# GSC_0.1 register map
Vendor: Texas Instruments
Peripheral module from a debugger description file (folder mspm33c321x).
Registers are 32-bit, read-write, no defined reset value unless marked. A register's access mark holds for its fields unless they carry their own. Offsets are as the file gives them; lines under a group give offsets from that group; [hi:lo] are bit positions; {n}, {i} and the like mark numbered series; 'fields as' and 'values as' point back to an identical list; <NAME> marks a mode.

## GSC
0x1000 GSC_SPC_ATTRIBVIOLS_CONFIG — SRAM Secure Access Attribute Violation Configuration Register
  [0] SECVIOL — Controls the behavior of secure access to non-secure SRAM #br#0: Access is allowed #br#1: Access generates bus-fault and NMI
0x1004 GSC_SPC_ATTRIBVIOLP_CONFIG — SRAM Privilege Access Attribute Violation Configuration Register
  [0] PRIVVIOL — Controls the behavior of privilege access to non-privilege SRAM #br#0: Access is allowed #br#1: Access generates bus-fault and NMI
0x1010 GSC_PPC_ATTRIBVIOLS_CONFIG — Peripheral Secure Access Attribute Violation Configuration Register
  [0] SECVIOL — Controls the behavior of secure access to non-secure peripheral #br#0: Access is allowed #br#1: Access generates bus-fault and NMI
0x1014 GSC_PPC_ATTRIBVIOLP_CONFIG — Peripheral Privilege Access Attribute Violation Configuration Register
  [0] PRIVVIOL — Controls the behavior of privilege access to non-privilege peripherals #br#0: Access is allowed #br#1: Access generates bus-fault and NMI
0x1020 GSC_FPC_ATTRIBVIOLS_CONFIG — Flash Secure Access Attribute Violation Configuration Register
  [0] SECVIOL — Controls the behavior of secure access to non-secure Flash #br#0: Access is allowed #br#1: Access generates bus-fault and NMI
0x1024 GSC_FPC_ATTRIBVIOLP_CONFIG — Flash Privilege Access Attribute Violation Configuration Register
  [0] PRIVVIOL — Controls the behavior of privilege access to non-privilege Flash #br#0: Access is allowed #br#1: Access generates bus-fault and NMI
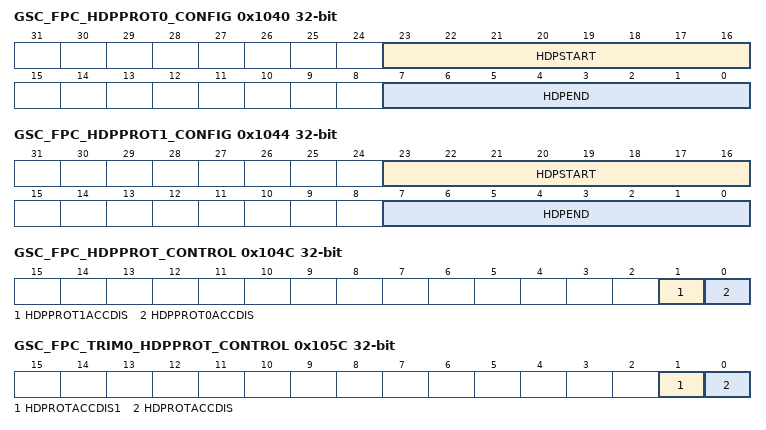
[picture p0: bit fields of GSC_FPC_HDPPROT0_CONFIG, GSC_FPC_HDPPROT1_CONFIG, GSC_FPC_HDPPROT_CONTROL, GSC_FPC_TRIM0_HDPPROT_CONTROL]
0x1040 GSC_FPC_HDPPROT0_CONFIG — Flash Hide Protection for Bank0 Configuration Register
  [23:16] HDPSTART — Sector number where hide protection starts
  [7:0] HDPEND — Sector number where hide protection ends
0x1044 GSC_FPC_HDPPROT1_CONFIG — Flash Hide Protection for Bank1 Configuration Register
  fields as GSC_FPC_HDPPROT0_CONFIG
0x104C GSC_FPC_HDPPROT_CONTROL — Flash Hide Protection Control Register
  [1] HDPPROT1ACCDIS — Enables the FPC_HDPPROT1_CONFIG to take effect. #br#0: HDP region access is enabled #br#1: HDP region access is disabled
  [0] HDPPROT0ACCDIS — Enables the FPC_HDPPROT0_CONFIG to take effect. #br#0: HDP region access is enabled #br#1: HDP region access is disabled
0x1050 GSC_FPC_HDPEN_CONTROL — Flash Hide Protection Enable Control Register
  [0] HDPEN — HDP mode enable. This bit is set in the OTP during provisioning. #br#0: HDP mode is not used #br#1: HDP mode is enabled
0x1054 GSC_FPC_NONMAIN0_HDPPROT_CONTROL — Flash NONMAIN Bank0 Hide Protection Control Register
  [3:0] HDPROTACCDIS — Enable HDP access to NONMAIN region #br#0: HDP region access is enabled #br#1: HDP region access is disabled
0x1058 GSC_FPC_NONMAIN1_HDPPROT_CONTROL — Flash NONMAIN Bank1 Hide Protection Control Register
  fields as GSC_FPC_NONMAIN0_HDPPROT_CONTROL
0x105C GSC_FPC_TRIM0_HDPPROT_CONTROL — Flash TRIM Bank0 Hide Protection Control Register
  [1] HDPROTACCDIS1 — No functionality implemented for this bit
  [0] HDPROTACCDIS — Enable HDP access to TRIM region #br#0: HDP region access is enabled #br#1: HDP region access is disabled
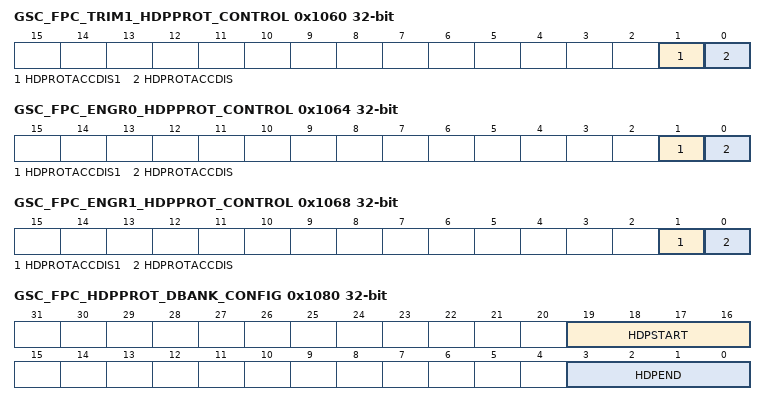
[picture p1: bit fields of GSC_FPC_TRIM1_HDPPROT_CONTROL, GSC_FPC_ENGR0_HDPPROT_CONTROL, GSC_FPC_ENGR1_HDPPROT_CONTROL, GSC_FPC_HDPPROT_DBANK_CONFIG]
0x1060 GSC_FPC_TRIM1_HDPPROT_CONTROL — Flash TRIM Bank1 Hide Protection Control Register
  fields as GSC_FPC_TRIM0_HDPPROT_CONTROL
0x1064 GSC_FPC_ENGR0_HDPPROT_CONTROL — Flash ENGR Bank0 Hide Protection Control Register
  [1] HDPROTACCDIS1 — No functionality implemented for this bit
  [0] HDPROTACCDIS — Enable HDP access to ENGR region #br#0: HDP region access is enabled #br#1: HDP region access is disabled
0x1068 GSC_FPC_ENGR1_HDPPROT_CONTROL — Flash ENGR Bank1 Hide Protection Control Register
  fields as GSC_FPC_ENGR0_HDPPROT_CONTROL
0x1080 GSC_FPC_HDPPROT_DBANK_CONFIG — Data Flash Hide Protection Configuration Register
  [19:16] HDPSTART — Sector number where hide protection starts
  [3:0] HDPEND — Sector number where hide protection ends
0x1084 GSC_FPC_HDPPROT_DBANK_CONTROL — Data Flash Hide Protection Control Register
  [0] HDPPROTACCDIS — Enables the HDP register to take effect for Databank #br#0: HDP region access is enabled #br#1: HDP region access is disabled
0x1088 GSC_FPC_HDPEN_DBANK_CONTROL — Data Flash Hide Protection Enable Control Register
  [0] HDPEN — HDP mode enable. This bit is set in the OTP during provisioning and copied from the OTP memory during boot by BOOTROM. #br#0: HDP mode is not used #br#1: HDP mode is enabled
0x108C GSC_FPC_NONMAIN_HDPPROT_DBANK_CONTROL — Data Flash NONMAIN Hide Protection Control Register
  fields as GSC_FPC_NONMAIN0_HDPPROT_CONTROL
0x1090 GSC_FPC_TRIM_HDPPROT_DBANK_CONTROL — Data Flash TRIM Hide Protection Control Register
  [1:0] HDPROTACCDIS — Enable HDP access to TRIM region #br#0: HDP region access is enabled #br#1: HDP region access is disabled
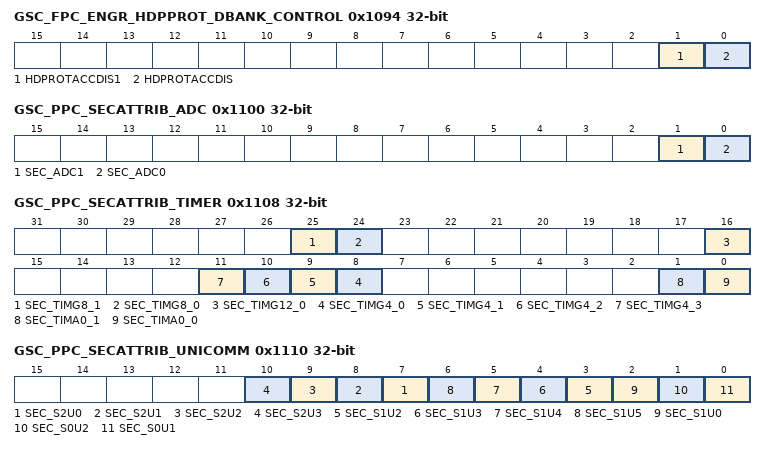
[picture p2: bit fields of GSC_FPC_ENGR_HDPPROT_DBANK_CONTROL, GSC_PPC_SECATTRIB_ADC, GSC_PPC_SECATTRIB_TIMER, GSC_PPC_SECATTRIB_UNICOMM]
0x1094 GSC_FPC_ENGR_HDPPROT_DBANK_CONTROL — Data Flash ENGR Hide Protection Control Register
  fields as GSC_FPC_ENGR0_HDPPROT_CONTROL
0x1100 GSC_PPC_SECATTRIB_ADC — Peripheral Secure Access ADC
  [1] SEC_ADC1 — Secure access enabled to ADC1 #br#0: Non-secure access is enabled #br#1: Secure access is enabled
  [0] SEC_ADC0 — Secure access enabled to ADC0 #br#0: Non-secure access is enabled #br#1: Secure access is enabled
0x1108 GSC_PPC_SECATTRIB_TIMER — Peripheral Secure Access Timer
  [25] SEC_TIMG8_1 — Secure access enabled to TIMG8_1 #br#0: Non-secure access is enabled #br#1: Secure access is enabled
  [24] SEC_TIMG8_0 — Secure access enabled to TIMG8_0 #br#0: Non-secure access is enabled #br#1: Secure access is enabled
  [16] SEC_TIMG12_0 — Secure access enabled to TIMG12_0 #br#0: Non-secure access is enabled #br#1: Secure access is enabled
  [n+8] SEC_TIMG4_{n} (n=0..3) — Secure access enabled to TIMG4_{n} #br#0: Non-secure access is enabled #br#1: Secure access is enabled
  [1] SEC_TIMA0_1 — Secure access enabled to TIMA0_1 #br#0: Non-secure access is enabled #br#1: Secure access is enabled
  [0] SEC_TIMA0_0 — Secure access enabled to TIMA0_0 #br#0: Non-secure access is enabled #br#1: Secure access is enabled
0x1110 GSC_PPC_SECATTRIB_UNICOMM — Peripheral Secure Access UniComm
  [n+7] SEC_S2U{n} (n=0..3) — Secure access enabled to UniComm S2U{n} #br#0: Non-secure access is enabled #br#1: Secure access is enabled
  [n+1] SEC_S1U{n} (n=2..5) — Secure access enabled to UniComm S1U{n} #br#0: Non-secure access is enabled #br#1: Secure access is enabled
  [2] SEC_S1U0 — Secure access enabled to UniComm S1U0 #br#0: Non-secure access is enabled #br#1: Secure access is enabled
  [1] SEC_S0U2 — Secure access enabled to UniComm S0U2 #br#0: Non-secure access is enabled #br#1: Secure access is enabled
  [0] SEC_S0U1 — Secure access enabled to UniComm S0U1 #br#0: Non-secure access is enabled #br#1: Secure access is enabled
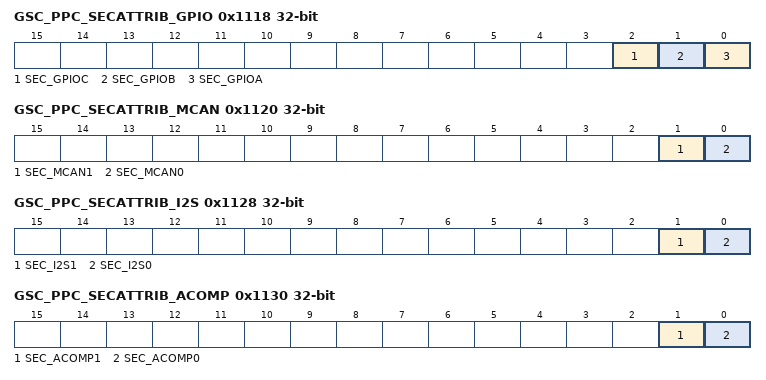
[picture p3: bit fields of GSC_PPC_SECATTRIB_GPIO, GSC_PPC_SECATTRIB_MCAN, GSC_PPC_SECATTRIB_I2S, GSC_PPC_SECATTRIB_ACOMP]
0x1118 GSC_PPC_SECATTRIB_GPIO — Peripheral Secure Access GPIO
  [2] SEC_GPIOC — Secure access enabled to GPIO C #br#0: Non-secure access is enabled #br#1: Secure access is enabled
  [1] SEC_GPIOB — Secure access enabled to GPIO B #br#0: Non-secure access is enabled #br#1: Secure access is enabled
  [0] SEC_GPIOA — Secure access enabled to GPIO A #br#0: Non-secure access is enabled #br#1: Secure access is enabled
0x1120 GSC_PPC_SECATTRIB_MCAN — Peripheral Secure Access CAN
  [1] SEC_MCAN1 — Secure access enabled to MCAN 1 #br#0: Non-secure access is enabled #br#1: Secure access is enabled
  [0] SEC_MCAN0 — Secure access enabled to MCAN 0 #br#0: Non-secure access is enabled #br#1: Secure access is enabled
0x1128 GSC_PPC_SECATTRIB_I2S — Peripheral Secure Access I2S
  [1] SEC_I2S1 — Secure access enabled to I2S 1 #br#0: Non-secure access is enabled #br#1: Secure access is enabled
  [0] SEC_I2S0 — Secure access enabled to I2S 0 #br#0: Non-secure access is enabled #br#1: Secure access is enabled
0x1130 GSC_PPC_SECATTRIB_ACOMP — Peripheral Secure Access Analog Comp
  [1] SEC_ACOMP1 — Secure access enabled to Comparator 1 #br#0: Non-secure access is enabled #br#1: Secure access is enabled
  [0] SEC_ACOMP0 — Secure access enabled to Comparator 0 #br#0: Non-secure access is enabled #br#1: Secure access is enabled
0x1138 GSC_PPC_SECATTRIB_WDT — Peripheral Secure Access Watchdog
  [0] SEC_WWDT — Secure access enabled to Windowed Watchdog #br#0: Non-secure access is enabled #br#1: Secure access is enabled
0x1140 GSC_PPC_SECATTRIB_LFSS — Peripheral Secure Access LFSS
  [0] SEC_LFSS — Secure access enabled to LFSS (including peripherals inside LFSS e.g. IWDT) #br#0: Non-secure access is enabled #br#1: Secure access is enabled
0x1148 GSC_PPC_SECATTRIB_CRC — Peripheral Secure Access CRC
  [0] SEC_CRC — Secure access enabled to CRC #br#0: Non-secure access is enabled #br#1: Secure access is enabled
0x1150 GSC_PPC_SECATTRIB_AES — Peripheral Secure Access AES
  [0] SEC_AES — Secure access enabled to AES #br#0: Non-secure access is enabled #br#1: Secure access is enabled
0x1158 GSC_PPC_SECATTRIB_SHA — Peripheral Secure Access SHA
  [0] SEC_SHA — Secure access enabled to SHA #br#0: Non-secure access is enabled #br#1: Secure access is enabled
0x1160 GSC_PPC_SECATTRIB_PKA — Peripheral Secure Access PKA
  [0] SEC_PKA — Secure access enabled to PKA #br#0: Non-secure access is enabled #br#1: Secure access is enabled
0x1168 GSC_PPC_SECATTRIB_IOMUX — Peripheral Secure Access IOMUX
  [0] SEC_IOMUX — Secure access enabled to IOMUX #br#0: Non-secure access is enabled #br#1: Secure access is enabled
0x1170 GSC_PPC_SECATTRIB_QSPI — Peripheral Secure Access QSPI
  [0] SEC_QSPI — Secure access enabled to QSPI #br#0: Non-secure access is enabled #br#1: Secure access is enabled
0x1178 GSC_PPC_SECATTRIB_TRNG — Peripheral Secure Access TRNG
  [0] SEC_TRNG — Secure access enabled to TRNG #br#0: Non-secure access is enabled #br#1: Secure access is enabled
0x1180 GSC_PPC_SECATTRIB_DEBUGSS — Peripheral Secure Access DEBUGSS
  [0] SEC_DEBUGSS — Secure access enabled to DEBUGSS #br#0: Non-secure access is enabled #br#1: Secure access is enabled
0x1188 GSC_PPC_SECATTRIB_VREF — Peripheral Secure Access VREF
  [0] SEC_VREF — Secure access enabled to VREF #br#0: Non-secure access is enabled #br#1: Secure access is enabled
0x1190 GSC_PPC_SECATTRIB_KEYSTORECTL — Peripheral Secure Access KEYSTORECTL
  [0] SEC_KEYSTORECTL — Secure access enabled to KEYSTORECTL #br#0: Non-secure access is enabled #br#1: Secure access is enabled
0x1198 GSC_PPC_SECATTRIB_EAM — Peripheral Secure Access EAM
  [0] SEC_EAM — Secure access enabled to EAM #br#0: Non-secure access is enabled #br#1: Secure access is enabled
0x11A0 GSC_PPC_SECATTRIB_WUC — Peripheral Secure Access WUC
  [0] SEC_WUC — Secure access enabled to WUC #br#0: Non-secure access is enabled #br#1: Secure access is enabled
0x11A8 GSC_PPC_SECATTRIB_FRIREGS — Peripheral Secure Access FRIREGS
  [0] SEC_FRIREGS — Secure access enabled to FRIREGS #br#0: Non-secure access is enabled #br#1: Secure access is enabled
0x11B0 GSC_PPC_SECATTRIB_MEMCFG — Peripheral Secure Access MEMCFG
  [0] SEC_MEMCFG — Secure access enabled to MEMCFG #br#0: Non-secure access is enabled #br#1: Secure access is enabled
0x1208 GSC_PPC_SECATTRIB_SYSCTL — Peripheral Secure Access System Control
  [0] SEC_SYSCTL — Secure access enabled to SYSCTL #br#0: Non-secure access is enabled #br#1: Secure access is enabled
0x120C GSC_PPC_PRIVATTRIB_SYSCTL — Peripheral Privilege Access System Control
  [0] PRIV_SYSCTL — Privilege access enabled to SYSCTL #br#0: Non-Privilege access is enabled #br#1: Privilege access is enabled
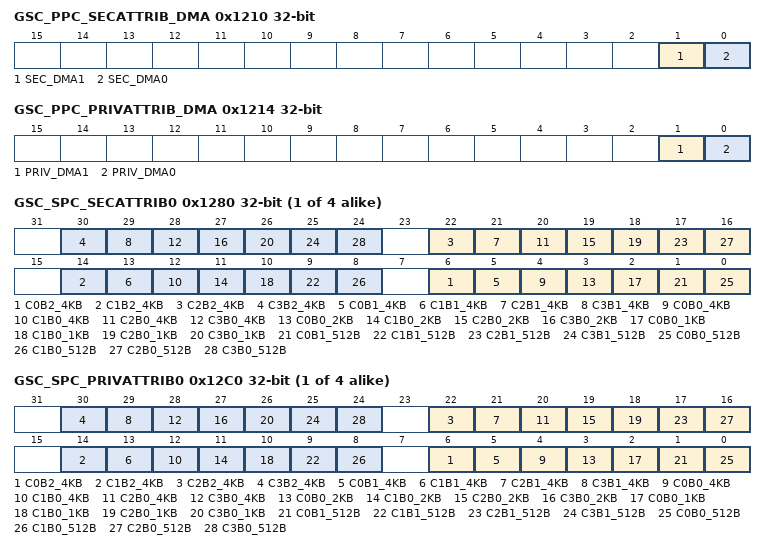
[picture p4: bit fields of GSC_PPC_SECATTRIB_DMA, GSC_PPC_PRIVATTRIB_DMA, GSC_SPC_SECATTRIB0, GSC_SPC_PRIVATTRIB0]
0x1210 GSC_PPC_SECATTRIB_DMA — Peripheral Secure Access DMA
  [1] SEC_DMA1 — Secure access enabled to DMA1 #br#0: Non-secure access is enabled #br#1: Secure access is enabled
  [0] SEC_DMA0 — Secure access enabled to DMA0 #br#0: Non-secure access is enabled #br#1: Secure access is enabled
0x1214 GSC_PPC_PRIVATTRIB_DMA — Peripheral Privilege Access DMA
  [1] PRIV_DMA1 — Privilege access enabled to DMA1 #br#0: Non-Privilege access is enabled #br#1: Privilege access is enabled
  [0] PRIV_DMA0 — Privilege access enabled to DMA0 #br#0: Non-Privilege access is enabled #br#1: Privilege access is enabled
0x1218 GSC_PPC_SECATTRIB_GSC — Peripheral Secure Access GSC
  [0] SEC_GSC — Secure access enabled to GSC #br#0: Non-secure access is enabled #br#1: Secure access is enabled
0x121C GSC_PPC_PRIVATTRIB_GSC — Peripheral Privilege Access GSC
  [0] PRIV_GSC — Privilege access enabled to GSC #br#0: Non-Privilege access is enabled #br#1: Privilege access is enabled
0x1220 GSC_PPC_SPARERW_GSC — Peripheral Spare RW Register
  [0] ZERO_PKASRAM — Controls the zeroization of PKA SRAM #br#0: PKA SRAM zeroization is enabled #br#1: PKA SRAM zeroization is disabled
0x1224 GSC_PPC_SPARERW1S_GSC access not given — Peripheral Spare RW1S Register
{0x1280+4i} GSC_SPC_SECATTRIB{i} (i=0..3) — SRAM Secure Attribute-{i} Register
  [8n+6] C{n}B2_4KB (n=0..3) — Secure access enabled to 3rd 4KB in chunk-{n} #br#0: Non-secure access is enabled #br#1: Secure access is enabled
  [8n+5] C{n}B1_4KB (n=0..3) — Secure access enabled to 2nd 4KB in chunk-{n} #br#0: Non-secure access is enabled #br#1: Secure access is enabled
  [8n+4] C{n}B0_4KB (n=0..3) — Secure access enabled to 1st 4KB in chunk-{n} #br#0: Non-secure access is enabled #br#1: Secure access is enabled
  [8n+3] C{n}B0_2KB (n=0..3) — Secure access enabled to 2KB in chunk-{n} #br#0: Non-secure access is enabled #br#1: Secure access is enabled
  [8n+2] C{n}B0_1KB (n=0..3) — Secure access enabled to 1KB in chunk-{n} #br#0: Non-secure access is enabled #br#1: Secure access is enabled
  [8n+1] C{n}B1_512B (n=0..3) — Secure access enabled to 2nd 512 byte in chunk-{n} #br#0: Non-secure access is enabled #br#1: Secure access is enabled
  [8n] C{n}B0_512B (n=0..3) — Secure access enabled to 1st 512 byte in chunk-{n} #br#0: Non-secure access is enabled #br#1: Secure access is enabled
{0x12C0+4i} GSC_SPC_PRIVATTRIB{i} (i=0..3) — SRAM Privilege Attribute-{i} Register
  [8n+6] C{n}B2_4KB (n=0..3) — privilege access enabled to 3rd 4KB in chunk-{n} #br#0: Non-privilege access is enabled #br#1: privilege access is enabled
  [8n+5] C{n}B1_4KB (n=0..3) — privilege access enabled to 2nd 4KB in chunk-{n} #br#0: Non-privilege access is enabled #br#1: privilege access is enabled
  [8n+4] C{n}B0_4KB (n=0..3) — privilege access enabled to 1st 4KB in chunk-{n} #br#0: Non-privilege access is enabled #br#1: privilege access is enabled
  [8n+3] C{n}B0_2KB (n=0..3) — privilege access enabled to 2KB in chunk-{n} #br#0: Non-privilege access is enabled #br#1: privilege access is enabled
  [8n+2] C{n}B0_1KB (n=0..3) — privilege access enabled to 1KB in chunk-{n} #br#0: Non-privilege access is enabled #br#1: privilege access is enabled
  [8n+1] C{n}B1_512B (n=0..3) — privilege access enabled to 2nd 512 byte in chunk-{n} #br#0: Non-privilege access is enabled #br#1: privilege access is enabled
  [8n] C{n}B0_512B (n=0..3) — privilege access enabled to 1st 512 byte in chunk-{n} #br#0: Non-privilege access is enabled #br#1: privilege access is enabled
0x1300 GSC_FPC_SECATTRIBA0 access not given — Flash Secure Attribute Register A0
0x1304 GSC_FPC_SECATTRIBA1 access not given — Flash Secure Attribute Register A1
0x1308 GSC_FPC_SECATTRIBB0 — Flash Secure Attribute Register B0
  [31:4] SEC_PAGE — Secure access enable for 64KB-512KB flash with each bit representing 8 sectors of 2KB #br#0: Non-secure access is enabled #br#1: Secure access is enabled
0x130C GSC_FPC_SECATTRIBB1 — Flash Secure Attribute Register B1
  fields as GSC_FPC_SECATTRIBB0
0x1310 GSC_FPC_NONMAIN_SECATTRIB0 — Flash Non-Main Secure Attribute Register 0
  [3:0] SEC_PAGE — Secure access enable for first 4 sectors of flash with each bit representing 1 sector of 2KB #br#0: Non-secure access is enabled #br#1: Secure access is enabled
0x1314 GSC_FPC_NONMAIN_SECATTRIB1 — Flash Non-Main Secure Attribute Register 1
  fields as GSC_FPC_NONMAIN_SECATTRIB0
0x1318 GSC_FPC_TRIM_SECATTRIB0 — Flash Trim Secure Attribute Register 0
  [0] SEC_PAGE — Secure access enable for the flash with each bit representing 1 sector of 2KB #br#0: Non-secure access is enabled #br#1: Secure access is enabled
0x131C GSC_FPC_TRIM_SECATTRIB1 — Flash Trim Secure Attribute Register 1
  fields as GSC_FPC_TRIM_SECATTRIB0
0x1320 GSC_FPC_ENGR_SECATTRIB0 — Flash Engr Secure Attribute Register 0
  fields as GSC_FPC_TRIM_SECATTRIB0
0x1324 GSC_FPC_ENGR_SECATTRIB1 — Flash Engr Secure Attribute Register 1
  fields as GSC_FPC_TRIM_SECATTRIB0
0x1380 GSC_FPC_SECATTRIBA_DFLASH — Data Flash Secure Attribute Register A
  [15:0] SEC_PAGE_DFLASH — Secure access enable for first 16 sectors data flash page with each bit representing 1 sector of 2KB #br#0: Non-secure access is enabled #br#1: Secure access is enabled
0x1384 GSC_FPC_ENGR_SECATTRIB_DFLASH — Data Flash ENGR Secure Attribute Register
  [0] SEC_PAGE_DFLASH — Secure access enable for 1 sector of 2KB #br#0: Non-secure access is enabled #br#1: Secure access is enabled
0x1388 GSC_FPC_NONMAIN_SECATTRIB_DFLASH — Data Flash Non-Main Secure Attribute Register
  [3:0] SEC_PAGE_DFLASH — Secure access enable for 4 sector with each bit representing 1 sector of 2KB #br#0: Non-secure access is enabled #br#1: Secure access is enabled
0x1400 GSC_FPC_PRIVATTRIBA0 access not given — Flash Privilege Attribute Register A0
0x1404 GSC_FPC_PRIVATTRIBA1 access not given — Flash Privilege Attribute Register A1
0x1408 GSC_FPC_PRIVATTRIBB0 — Flash Privilege Attribute Register B0
  [31:4] PRIV_PAGE — Privilege access enable for 64KB-512KB flash with each bit representing 8 sectors of 2KB #br#0: Non-privilege access is enabled #br#1: privilege access is enabled
0x140C GSC_FPC_PRIVATTRIBB1 — Flash Privilege Attribute Register B1
  fields as GSC_FPC_PRIVATTRIBB0
0x1410 GSC_FPC_NONMAIN_PRIVATTRIB0 — Flash Non-Main Privilege Attribute Register B0
  [3:0] PRIV_PAGE — Privilege access enable for first 4 sectors of flash with each bit representing 1 sector of 2KB #br#0: Non-Privilege access is enabled #br#1: Privilege access is enabled
0x1414 GSC_FPC_NONMAIN_PRIVATTRIB1 — Flash Non-Main Privilege Attribute Register B1
  fields as GSC_FPC_NONMAIN_PRIVATTRIB0
0x1418 GSC_FPC_TRIM_PRIVATTRIB0 — Flash Trim Privilege Attribute Register B0
  [0] PRIV_PAGE — Privilege access enable for the flash with each bit representing 1 sector of 2KB #br#0: Non-Privilege access is enabled #br#1: Privilege access is enabled
0x141C GSC_FPC_TRIM_PRIVATTRIB1 — Flash Trim Privilege Attribute Register B1
  fields as GSC_FPC_TRIM_PRIVATTRIB0
0x1420 GSC_FPC_ENGR_PRIVATTRIB0 — Flash Engr Privilege Attribute Register B0
  fields as GSC_FPC_TRIM_PRIVATTRIB0
0x1424 GSC_FPC_ENGR_PRIVATTRIB1 — Flash Engr Privilege Attribute Register B1
  fields as GSC_FPC_TRIM_PRIVATTRIB0
0x1480 GSC_FPC_PRIVATTRIBA_DFLASH — Data Flash Privilege Attribute Register
  [15:0] PRIV_PAGE_DFLASH — Privilege access enable for first 16 sectors data flash page with each bit representing 1 sector of 2KB #br#0: Non-Privilege access is enabled #br#1: Privilege access is enabled
0x1484 GSC_FPC_NONMAIN_PRIVATTRIB_DFLASH — Data Flash NONMAIN Privilege Attribute Register
  [3:0] PRIV_PAGE_DFLASH — Privilege access enable for 4 sectors each of 2KB #br#0: Non-Privilege access is enabled #br#1: Privilege access is enabled
0x1488 GSC_FPC_ENGR_PRIVATTRIB_DFLASH — Data Flash ENGR Privilege Attribute Register
  [0] PRIV_PAGE_DFLASH — Privilege access enable for 1 sector of 2KB #br#0: Non-Privilege access is enabled #br#1: Privilege access is enabled
0x1600 GSC_FPC_WEPROTA0 access not given — Flash Write Protect Attribute Register A0
0x1604 GSC_FPC_WEPROTA1 access not given — Flash Write Protect Attribute Register A1
0x1608 GSC_FPC_WEPROTB0 access not given — Flash Write Protect Attribute Register B0
0x160C GSC_FPC_WEPROTB1 access not given — Flash Write Protect Attribute Register B1
0x1610 GSC_FPC_WEPROTNONMAIN0 — Flash Non-Main Write Protect Attribute Register B0
  [3:0] WEPROT_PAGE — Write protection enable for first 4 sectors of flash with each bit representing 1 sector of 2KB #br#0: Page is not erase/program protected #br#1: Page is erase/program protected
0x1614 GSC_FPC_WEPROTNONMAIN1 — Flash Non-Main Write Protect Attribute Register B1
  fields as GSC_FPC_WEPROTNONMAIN0
0x1618 GSC_FPC_WEPROTTRIM0 — Flash Trim Write Protect Attribute Register B0
  [1:0] WEPROT_PAGE — Write protection enable for first 2 sectors of flash with each bit representing 1 sector of 2KB #br#0: Page is not erase/program protected #br#1: Page is erase/program protected
0x161C GSC_FPC_WEPROTTRIM1 — Flash Trim Write Protect Attribute Register B1
  fields as GSC_FPC_WEPROTTRIM0
0x1620 GSC_FPC_WEPROTENGR0 — Flash Engr Write Protect Attribute Register B0
  fields as GSC_FPC_WEPROTTRIM0
0x1624 GSC_FPC_WEPROTENGR1 — Flash Engr Write Protect Attribute Register B1
  fields as GSC_FPC_WEPROTTRIM0
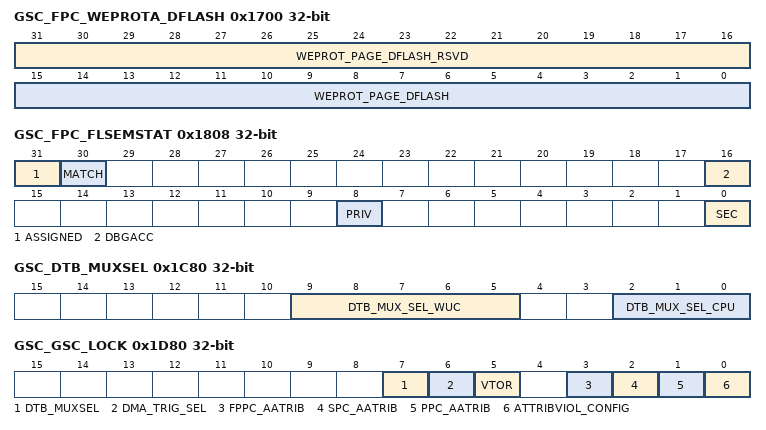
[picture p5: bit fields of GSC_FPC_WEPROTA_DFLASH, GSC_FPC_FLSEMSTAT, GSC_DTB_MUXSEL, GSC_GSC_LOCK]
0x1700 GSC_FPC_WEPROTA_DFLASH — Data Flash Write Protect Attribute Register A
  [31:16] WEPROT_PAGE_DFLASH_RSVD — No functionality implemented for these bits
  [15:0] WEPROT_PAGE_DFLASH — Write protection enable for first 16 sectors data flash page with each bit representing 1 sector of 2KB #br#0: Page is not erase/program protected #br#1: Page is erase/program protected
0x1704 GSC_FPC_WEPROT_NONMAIN_DFLASH — DATA Flash Non- Main Write Protect Attribute Register
  [3:0] WEPROT_PAGE_DFLASH — Write protection enable for NONMAIN sectors data flash page with each bit representing 1 sector of 2KB #br#0: Page is not erase/program protected #br#1: Page is erase/program protected
0x1708 GSC_FPC_WEPROT_ENGR_DFLASH — DATA Flash ENGR Write Protect Attribute Register
  [1:0] WEPROT_PAGE_DFLASH — Write protection enable for ENGR data flash page with each bit representing 1 sector of 2KB #br#0: Page is not erase/program protected #br#1: Page is erase/program protected
0x1800 GSC_FPC_FLSEMREQ — Flash semaphore request register
  [0] REQ — If the FLSEMSTAT.ASSIGNED bit is cleared, writing a '1' to this bit causes: #br# 1) Load the SECURE attribute of the code performing the write into the FLSEMSTAT.SEC bit field, and #br# 2) Load the Privilage attribute of the code performing the write into the FLSEMSTAT.PRIV bit field, and #br# 3) Set the FLSEMSTAT.ASSIGNED bit. #br#If the FLSEMSTAT.ASSIGNED is already set when a write to this bit occurs, the write will be ignored. #br# #br#If the above conditions are not met during the write, the write will be ignored with no error indicator. It is advised that the writing code perform a read of the FLSEMSTAT register to ensure it was set after writing to this bit.
0x1804 GSC_FPC_FLSEMCLR — Flash semaphore release register
  [0] CLR — If the following conditions are met, a write of '1' to this bit causes the FLSEMSTAT register to its reset state: #br# 1) The FLSEMSTAT.SEC of the code performing the write is 0x1 and FLSEMSTAT.PRIV of the code performing the write is 0x1 (i.e. secure privilage code can force relinquishing of the semaphore) or #br# 2) FLSEMSTAT.ASSIGNED bit is set, and #br# a) FLSEMSTAT.SEC matches security attribute of the code performing the write, and #br# b) FLSEMSTAT.PRIV matches privilege attribute code performing the write. #br# #br#If the above conditions are not met during the write, the write will be ignored with no error indicated. It is advised that the writing code perform a read of the FLSEMSTAT register to ensure it was cleared after writing to this bit.
0x1808 GSC_FPC_FLSEMSTAT ro — Flash semaphore statys registers
  [31] ASSIGNED — SEC and PRIV fields are valid when this bit is set. #br# 0 : SEC and PRIV are unassigned and flash controller is not accessible #br# 1 : SEC and PRIV values are valid and the flash controller is currently assigned to them
  [30] MATCH — On a read, this bit will reflect whether the reader's SEC and PRIV matches the ownership of the flash controller. #br# 0 : Code performing read does not own the flash controller semaphore #br# 1 : Code performing read owns the flash controller semphore. #br#This avoids code from being required to know whether the current code segment owns the flash controller configuration.
  [16] DBGACC — Defines the flash controller semaphore owners debug access indication #br# 0x0 : functional access #br# 0x1 :Debug access
  [8] PRIV — Defines the flash controller semaphore owners privilage attribute #br# 0x0 : non-privilage #br# 0x1 :prvilage
  [0] SEC — Defines the flash controller semaphore owners security attribute #br# 0x0 : non-secure #br# 0x1 :secure
0x1A80 GSC_DMA_TRIG_SEL — DMA Trigger Selection register
  [27:0] SEL_TRIG — Select signal for DMA triggers to be routed to DMA0/DMA1 #br#0: DMA0 will be selected #br#1: DMA1 will be selected #br#Note: SEL_TRIG[9:6] is not used. #br#If a specific DMA is selected, the triggers should only go to that DMA
0x1A84 GSC_DMA_FIX_TRIG_SEL — DMA Fixed Trigger Selection register
  [10:0] SEL_TRIG — Select signal for Fixed DMA triggers to be routed to DMA0/DMA1 #br#0: DMA0 will be selected #br#1: DMA1 will be selected #br# #br#If a specific DMA is selected, the triggers should only go to that DMA
0x1B80 GSC_VTOR_S access not given — Secure Vector Table Offset Register
0x1B84 GSC_VTOR_NS access not given — Non - Secure Vector Table Offset Register
0x1C80 GSC_DTB_MUXSEL — Digital Test Bus MUX Selection
  [9:5] DTB_MUX_SEL_WUC — DTB Mux Sel for WUC signals to be brought out on DTB. Refer to implementaion spec for mux selection table.
  [2:0] DTB_MUX_SEL_CPU — DTB Mux Sel for CPU signals to be brought out on DTB. Refer to implementaion spec for mux selection table.
{0x1D00+4i} GSC_DICE_CHECKSUM{i} access not given (i=0..7) — DICE checksum data register-{i}
0x1D80 GSC_GSC_LOCK — GSC Lock configuration register
  [7] DTB_MUXSEL — Configuration impacts registers DTB_MUX_SEL #br#0: Register configuration is not locked. #br#1: Register configuration is locked. #br# #br#Once register is locked - reads give the MMR data and writes are ignored
  [6] DMA_TRIG_SEL — Configuration impacts registers DMA_TRIG_SEL* #br#0: Register configuration is not locked. #br#1: Register configuration is locked. #br# #br#Once register is locked - reads give the MMR data and writes are ignored
  [5] VTOR — Configuration impacts registers VTOR_* #br#0: Register configuration is not locked. #br#1: Register configuration is locked. #br# #br#Once register is locked - reads give the MMR data and writes are ignored
  [3] FPPC_AATRIB — Configuration impacts registers FPC_SECATTRIB_* and FPC_PRIVATTRIB_* #br#0: Register configuration is not locked. #br#1: Register configuration is locked. #br# #br#Once register is locked - reads give the MMR data and writes are ignored
  [2] SPC_AATRIB — Configuration impacts registers SPC_SECATTRIB_* and SPC_PRIVATTRIB_* #br#0: Register configuration is not locked. #br#1: Register configuration is locked. #br# #br#Once register is locked - reads give the MMR data and writes are ignored
  [1] PPC_AATRIB — Configuration impacts registers PPC_SECATTRIB_* and PPC_PRIVATTRIB_* #br#0: Register configuration is not locked. #br#1: Register configuration is locked. #br# #br#Once register is locked - reads give the MMR data and writes are ignored
  [0] ATTRIBVIOL_CONFIG — Configuration impacts registers SPC_ATTRIBVIOLS_CONFIG, SPC_ATTRIBVIOLP_CONFIG, PPC_ATTRIBVIOLS_CONFIG, PPC_ATTRIBVIOLP_CONFIG, FPC_ATTRIBVIOLS_CONFIG, FPC_ATTRIBVIOLP_CONFIG #br#0: Register configuration is not locked. #br#1: Register configuration is locked. #br# #br#Once register is locked - reads give the MMR data and writes are ignored
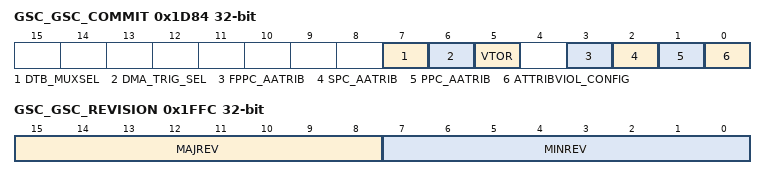
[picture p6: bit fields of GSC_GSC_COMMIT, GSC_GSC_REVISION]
0x1D84 GSC_GSC_COMMIT — GSC commit configuration register
  [7] DTB_MUXSEL — 0: Register lock configuration is not committed. #br#1: Register configuration is committed. #br#Once configuration is committed, only reset can change the configuration.
  [6] DMA_TRIG_SEL — 0: Register lock configuration is not committed. #br#1: Register configuration is committed. #br#Commit configuration blocks the writes going to the lock register. Once configuration is committed, only reset can change the configuration.
  [5] VTOR — 0: Register lock configuration is not committed. #br#1: Register configuration is committed. #br#Commit configuration blocks the writes going to the lock register. Once configuration is committed, only reset can change the configuration.
  [3] FPPC_AATRIB — 0: Register lock configuration is not committed. #br#1: Register configuration is committed. #br#Commit configuration blocks the writes going to the lock register. Once configuration is committed, only reset can change the configuration.
  [2] SPC_AATRIB — 0: Register lock configuration is not committed. #br#1: Register configuration is committed. #br#Commit configuration blocks the writes going to the lock register. Once configuration is committed, only reset can change the configuration.
  [1] PPC_AATRIB — 0: Register lock configuration is not committed. #br#1: Register configuration is committed. #br#Commit configuration blocks the writes going to the lock register. Once configuration is committed, only reset can change the configuration.
  [0] ATTRIBVIOL_CONFIG — 0: Register lock configuration is not committed. #br#1: Register configuration is committed. #br#Commit configuration blocks the writes going to the lock register. Once configuration is committed, only reset can change the configuration.
0x1FFC GSC_GSC_REVISION ro — GSC Revision register
  [15:8] MAJREV — This hardcoded field defines the major revision of the IP.
  [7:0] MINREV — This hardcoded field defines the minor revision of the IP.
